# TLE987x register map
Vendor: Infineon; Series: MOTIX MCU; File version: 4.2
CPU: CM3 r0p0, little endian, no MPU, no FPU, 4 interrupt priority bits
Registers are 32-bit, read-write, reset 0x0 unless marked. A register's access mark holds for its fields unless they carry their own. Offsets are from the block's base; [hi:lo] are bit positions.

## TIMER3 — TIMER3 Module
Base 0x48006000
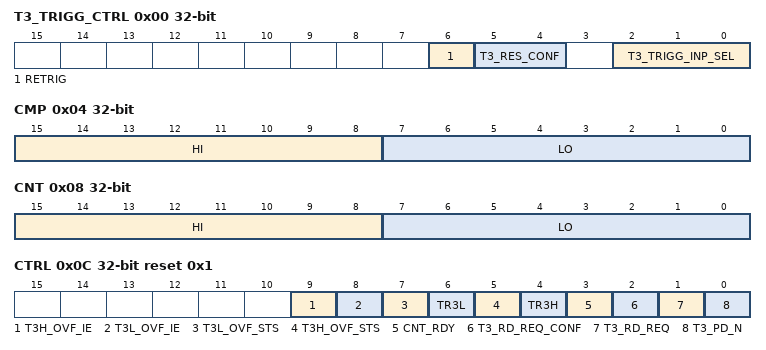
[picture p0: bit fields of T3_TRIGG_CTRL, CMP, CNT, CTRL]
0x00 T3_TRIGG_CTRL — T3 Trigger Control
  [6] RETRIG — Retrigger Condition (in mode 1b) for CCU6-T12 ZM and CCU6 PM
    0=DIS (Retrigger disabled); 1=EN (Retrigger enabled)
  [5:4] T3_RES_CONF — Timer 3 Trigger Reset Selection for Mode 1b
    0=No_Reset_on_PWM_Edge (Counter is not reset while PWM Module is running.); 1=Reset_On_Rising_Edge (Counter is reset on rising edge input); 2=Reset_On_Falling_Edge (Counter is reset on falling edge input.); 3=Reset_on_both_Edges (Counter is reset on both edge inputs.)
  [2:0] T3_TRIGG_INP_SEL — Timer 3 Trigger Input Event Selection (only in mode3b)
    0=CCU6_CC6_0 (Capture Compare Unit Channel 0 (CC60).); 1=CCU6_CC61 (Capture Compare Unit Channel 1 (CC61).); 2=CCU6_CC62 (Capture Compare Unit Channel 2 (CC62).); 3=CCU6_T12_ZM (Capture Compare Unit T12 Zero Match.); 4=CCU6_T12_PM (Capture Compare Unit T12 Period Match.); 5=CCU6_COUT6_0 (Capture Compare Unit Channel 0 (COUT60).); 6=CCU6_COUT61 (Capture Compare Unit Channel 1 (COUT61).); 7=CCU6_COUT62 (Capture Compare Unit Channel 2 (COUT62).)
0x04 CMP — Timer 3 Compare Value
  [15:8] HI — Timer 3 Compare Value High Byte
  [7:0] LO — Timer 3 Compare Value Low Byte
0x08 CNT — Timer 3
  [15:8] HI — Timer 3 High Register or Preload Value
  [7:0] LO — Timer 3 Low Register or Preload Value
0x0C CTRL access per field reset 0x1 — Timer 3 Control Register
  [9] T3H_OVF_IE rw — Timer 3 Overflow Interrupt Enable (High Byte Timer)
    0=DIS (Interrupt disabled); 1=EN (Interrupt enabled)
  [8] T3L_OVF_IE rw — Timer 3 Overflow Interrupt Enable (Low Byte Timer)
    0=DIS (Interrupt disabled.); 1=EN (Interrupt enabled)
  [7] T3L_OVF_STS ro — Timer 3 Overflow Flag (Low Byte Timer)
    0=clear (No overflow occurred.); 1=Set (Overflow occured. Set by hardware when Low Byte of Timer 3 overflows. Cleared by software.)
  [6] TR3L rw — Timer 3 Run Control (Low Byte Timer)
    0=Stop (Timer is halted); 1=Run (Timer runs)
  [5] T3H_OVF_STS ro — Timer 3 Overflow Flag (High Byte Timer)
    0=clear (No Overflow occured.); 1=Set (Overflow occured. Set by hardware when High Byte of Timer 3 overflows. Cleared by software.)
  [4] TR3H rw — Timer 3 Run Control (High Byte Timer)
    0=Stop (Timer is halted); 1=Run (Timer runs)
  [3] CNT_RDY rw — Timer 3 Count Ready
    0=Busy (Timer hasn't finished counting in Mode 1b, 3b); 1=Ready (Timer has finished counting in Mode 1b, 3b)
  [2] T3_RD_REQ_CONF rw — Timer 3 Read Mode
    0=Software (Timer 3 Read Request can be triggered by software); 1=Hardware (Timer 3 Read Request can be triggered by hardware (in mode 3b))
  [1] T3_RD_REQ rw — Timer 3 Value Read Request
    0=DISABLED (Timer value is not read from Timer 3); 1=ENABLED (Timer value is read from Timer 3)
  [0] T3_PD_N rw — Timer 3 Power Down
    0=Power_Down (Timer 3 is in Power Down); 1=no_Power_Down (Timer 3 is not in Power Down)
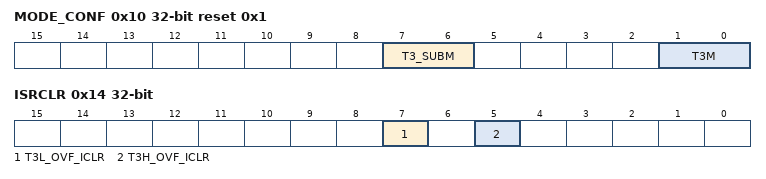
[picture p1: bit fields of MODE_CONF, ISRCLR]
0x10 MODE_CONF reset 0x1 — Timer 3 Mode Configuration Register
  [7:6] T3_SUBM — Sub-Mode Select Bits
    0=no Sub-Mode enabled; 1=Mode_1b (enables 16 bit Timer triggered by an event. This mode has only an effect with Mode 1 (16 Bit Mode)); 2=Mode_3b (enables two 8-Bit Timers for clock measurement. This Mode has only an effect with Mode 3.)
  [1:0] T3M — Mode Select Bits
    0=Mode_0 (13-bit timer); 1=Mode_1 (16-bit timer); 2=Mode_2 (8-bit auto-reload timer); 3=Mode_3 (Timer 3 is split into two halves. TL3 is an 8bit timer controlled by the standard Timer 3 low byte control bits, and TH3 is the other 8-bit timer controlled by the standard Timer 3 high byte control bits.)
0x14 ISRCLR wo — Timer 3 Interrupt Status Clear Register
  [7] T3L_OVF_ICLR — Timer 3 Overflow Flag (Low Byte Timer) Interrupt Clear
    0=no_action (Overflow not cleared.); 1=Clear (Overflow cleared. Set by software, cleared by hardware.)
  [5] T3H_OVF_ICLR — Timer 3 Overflow Flag (High Byte Timer) Interrupt Clear
    0=no_action (Overflow not cleared.); 1=Clear (Overflow cleared. Set by software, cleared by hardware)
